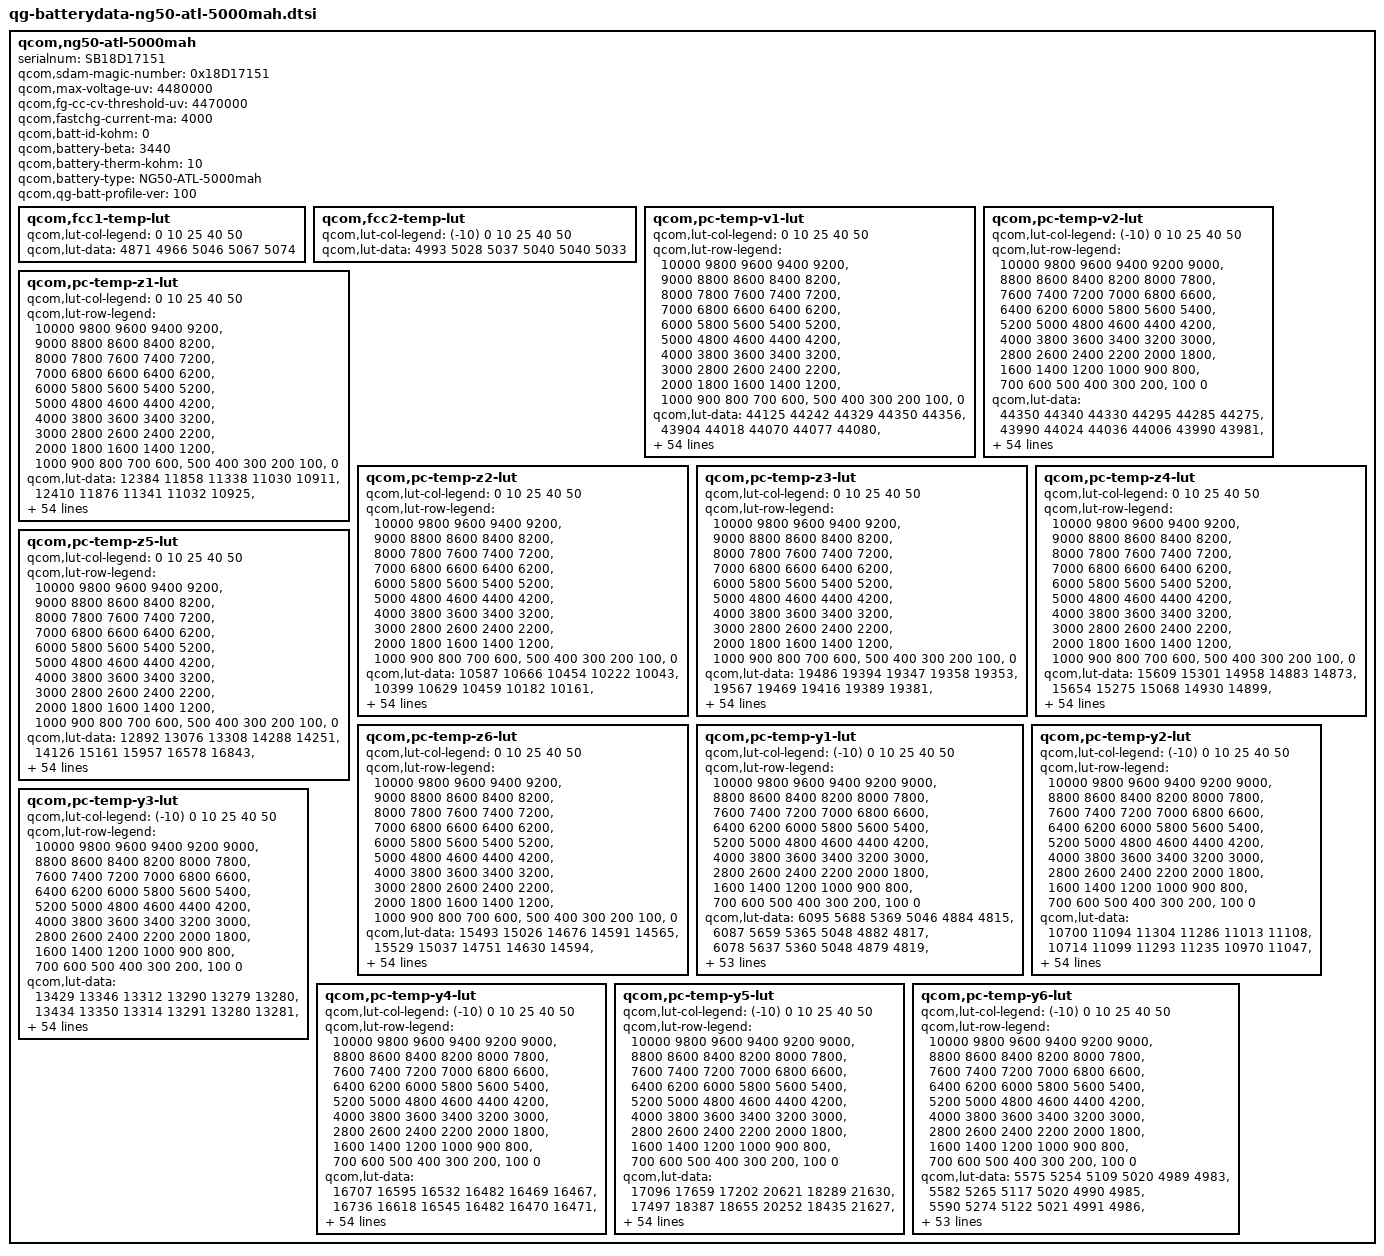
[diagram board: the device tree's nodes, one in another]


qcom,ng50-atl-5000mah {
    /* 5263304_Lenovo_Guogu_ATL_5000mAH_PM7250B_averaged_MasterSlave_Jun22th2021 */
    serialnum = "SB18D17151";
    qcom,sdam-magic-number = <0x18D17151>;
    qcom,max-voltage-uv = <4480000>;
    qcom,fg-cc-cv-threshold-uv = <4470000>;
    qcom,fastchg-current-ma = <4000>;
    qcom,batt-id-kohm = <0>;
    qcom,battery-beta = <3440>;
    qcom,battery-therm-kohm = <10>;
    qcom,battery-type = "NG50-ATL-5000mah";
    qcom,qg-batt-profile-ver = <100>;

	qcom,fcc1-temp-lut {
		qcom,lut-col-legend = <0 10 25 40 50>;
		qcom,lut-data = <4871 4966 5046 5067 5074>;
	};

	qcom,fcc2-temp-lut {
		qcom,lut-col-legend = <(-10) 0 10 25 40 50>;
		qcom,lut-data = <4993 5028 5037 5040 5040 5033>;
	};

	qcom,pc-temp-v1-lut {
		qcom,lut-col-legend = <0 10 25 40 50>;
		qcom,lut-row-legend = <10000 9800 9600 9400 9200>,
			<9000 8800 8600 8400 8200>,
			<8000 7800 7600 7400 7200>,
			<7000 6800 6600 6400 6200>,
			<6000 5800 5600 5400 5200>,
			<5000 4800 4600 4400 4200>,
			<4000 3800 3600 3400 3200>,
			<3000 2800 2600 2400 2200>,
			<2000 1800 1600 1400 1200>,
			<1000 900 800 700 600>,
			<500 400 300 200 100>,
			<0>;
		qcom,lut-data = <44125 44242 44329 44350 44356>,
			<43904 44018 44070 44077 44080>,
			<43680 43794 43852 43854 43854>,
			<43454 43573 43639 43642 43642>,
			<43224 43354 43415 43423 43422>,
			<42985 43125 43189 43202 43202>,
			<42743 42886 42955 42973 42975>,
			<42504 42643 42714 42734 42741>,
			<42265 42402 42473 42492 42504>,
			<42031 42161 42233 42251 42265>,
			<41803 41926 41994 42012 42024>,
			<41581 41694 41759 41777 41787>,
			<41365 41468 41526 41546 41554>,
			<41157 41249 41299 41319 41326>,
			<40952 41036 41079 41097 41105>,
			<40751 40830 40867 40881 40891>,
			<40554 40627 40664 40675 40683>,
			<40368 40434 40469 40475 40481>,
			<40190 40259 40283 40286 40289>,
			<40018 40097 40113 40117 40118>,
			<39855 39918 39940 39949 39950>,
			<39696 39700 39726 39736 39738>,
			<39509 39474 39479 39471 39471>,
			<39233 39260 39263 39246 39245>,
			<38979 39051 39078 39083 39092>,
			<38862 38900 38923 38947 38964>,
			<38795 38807 38810 38831 38837>,
			<38734 38731 38719 38732 38714>,
			<38671 38650 38630 38634 38607>,
			<38610 38571 38540 38531 38513>,
			<38550 38495 38457 38435 38430>,
			<38490 38422 38380 38354 38351>,
			<38433 38354 38309 38284 38278>,
			<38379 38295 38246 38217 38208>,
			<38329 38244 38193 38157 38140>,
			<38284 38197 38142 38098 38074>,
			<38246 38156 38092 38037 38006>,
			<38203 38113 38043 37975 37935>,
			<38137 38051 37977 37898 37849>,
			<38047 37962 37886 37793 37735>,
			<37943 37859 37782 37676 37611>,
			<37819 37738 37670 37566 37495>,
			<37674 37598 37541 37446 37370>,
			<37496 37425 37374 37285 37199>,
			<37333 37259 37220 37146 37064>,
			<37211 37147 37109 37050 36988>,
			<37176 37110 37073 37019 36961>,
			<37161 37088 37052 36992 36937>,
			<37127 37061 37029 36973 36913>,
			<37083 37024 36993 36924 36855>,
			<36940 36861 36801 36699 36606>,
			<36521 36434 36375 36268 36177>,
			<35947 35860 35804 35698 35606>,
			<35158 35064 35025 34922 34829>,
			<33838 33765 33823 33728 33632>,
			<30000 30000 30000 30000 30000>;
	};

	qcom,pc-temp-v2-lut {
		qcom,lut-col-legend = <(-10) 0 10 25 40 50>;
		qcom,lut-row-legend = <10000 9800 9600 9400 9200 9000>,
			<8800 8600 8400 8200 8000 7800>,
			<7600 7400 7200 7000 6800 6600>,
			<6400 6200 6000 5800 5600 5400>,
			<5200 5000 4800 4600 4400 4200>,
			<4000 3800 3600 3400 3200 3000>,
			<2800 2600 2400 2200 2000 1800>,
			<1600 1400 1200 1000 900 800>,
			<700 600 500 400 300 200>,
			<100 0>;
		qcom,lut-data = <44350 44340 44330 44295 44285 44275>,
			<43990 44024 44036 44006 43990 43981>,
			<43666 43736 43767 43738 43718 43711>,
			<43387 43482 43524 43493 43471 43466>,
			<43147 43261 43309 43272 43251 43248>,
			<42912 43037 43089 43049 43029 43029>,
			<42664 42797 42851 42811 42794 42796>,
			<42417 42551 42607 42570 42555 42557>,
			<42175 42307 42364 42328 42315 42318>,
			<41940 42064 42120 42085 42074 42075>,
			<41704 41825 41881 41846 41836 41836>,
			<41453 41588 41645 41611 41602 41600>,
			<41207 41359 41414 41380 41373 41369>,
			<41014 41142 41187 41153 41149 41145>,
			<40872 40935 40966 40931 40929 40927>,
			<40699 40733 40752 40717 40716 40715>,
			<40386 40542 40544 40510 40510 40508>,
			<40005 40345 40342 40311 40311 40309>,
			<39737 40111 40153 40126 40125 40124>,
			<39543 39836 39975 39951 39950 39950>,
			<39359 39577 39772 39759 39764 39766>,
			<39159 39346 39508 39527 39554 39559>,
			<38961 39134 39240 39290 39336 39345>,
			<38769 38945 39032 39080 39123 39135>,
			<38577 38773 38856 38884 38911 38925>,
			<38418 38620 38702 38723 38739 38752>,
			<38304 38486 38568 38594 38610 38620>,
			<38211 38364 38449 38483 38501 38507>,
			<38137 38243 38340 38382 38399 38402>,
			<38075 38127 38240 38289 38306 38305>,
			<38020 38036 38149 38203 38222 38217>,
			<37965 37969 38064 38120 38147 38141>,
			<37913 37916 37987 38043 38075 38067>,
			<37857 37872 37919 37974 38002 37992>,
			<37800 37838 37857 37912 37927 37915>,
			<37741 37802 37802 37843 37845 37828>,
			<37683 37764 37756 37766 37753 37719>,
			<37622 37722 37710 37684 37657 37606>,
			<37553 37668 37648 37601 37563 37511>,
			<37475 37602 37573 37515 37467 37422>,
			<37385 37512 37484 37424 37374 37332>,
			<37275 37366 37370 37330 37284 37241>,
			<37153 37204 37239 37216 37171 37126>,
			<37028 37043 37090 37071 37017 36965>,
			<36908 36882 36943 36955 36916 36865>,
			<36805 36780 36844 36887 36855 36805>,
			<36757 36745 36822 36870 36845 36792>,
			<36714 36711 36799 36859 36831 36777>,
			<36673 36666 36758 36832 36806 36752>,
			<36621 36587 36685 36767 36744 36678>,
			<36524 36399 36474 36519 36490 36410>,
			<36260 35988 35996 36044 36027 35935>,
			<35749 35357 35339 35409 35406 35309>,
			<35004 34477 34464 34542 34552 34447>,
			<33902 33111 33145 33244 33317 33248>,
			<31942 29637 29195 29227 29401 29421>;
	};

	qcom,pc-temp-z1-lut {
		qcom,lut-col-legend = <0 10 25 40 50>;
		qcom,lut-row-legend = <10000 9800 9600 9400 9200>,
			<9000 8800 8600 8400 8200>,
			<8000 7800 7600 7400 7200>,
			<7000 6800 6600 6400 6200>,
			<6000 5800 5600 5400 5200>,
			<5000 4800 4600 4400 4200>,
			<4000 3800 3600 3400 3200>,
			<3000 2800 2600 2400 2200>,
			<2000 1800 1600 1400 1200>,
			<1000 900 800 700 600>,
			<500 400 300 200 100>,
			<0>;
		qcom,lut-data = <12384 11858 11338 11030 10911>,
			<12410 11876 11341 11032 10925>,
			<12414 11885 11338 11035 10933>,
			<12416 11882 11334 11036 10939>,
			<12412 11874 11325 11033 10937>,
			<12392 11864 11314 11027 10933>,
			<12367 11837 11304 11022 10930>,
			<12355 11810 11294 11017 10929>,
			<12345 11798 11286 11014 10928>,
			<12334 11791 11279 11012 10927>,
			<12309 11784 11273 11011 10926>,
			<12280 11774 11269 11010 10925>,
			<12270 11767 11266 11009 10924>,
			<12269 11765 11264 11008 10924>,
			<12266 11765 11263 11007 10924>,
			<12249 11764 11262 11006 10925>,
			<12221 11753 11262 11006 10926>,
			<12208 11742 11265 11008 10928>,
			<12208 11743 11268 11011 10930>,
			<12210 11749 11269 11012 10933>,
			<12213 11752 11271 11014 10935>,
			<12222 11754 11274 11015 10937>,
			<12226 11754 11277 11016 10938>,
			<12228 11754 11280 11017 10939>,
			<12229 11754 11282 11020 10941>,
			<12226 11754 11286 11024 10944>,
			<12217 11758 11291 11027 10947>,
			<12214 11763 11298 11031 10950>,
			<12223 11766 11304 11035 10953>,
			<12236 11770 11307 11039 10957>,
			<12243 11773 11311 11042 10961>,
			<12250 11778 11316 11047 10965>,
			<12254 11781 11322 11051 10969>,
			<12251 11781 11328 11056 10973>,
			<12247 11779 11334 11061 10978>,
			<12247 11778 11340 11065 10982>,
			<12255 11784 11346 11070 10986>,
			<12263 11795 11352 11075 10990>,
			<12275 11807 11360 11080 10994>,
			<12297 11823 11368 11086 10999>,
			<12312 11835 11377 11091 11004>,
			<12319 11841 11387 11096 11007>,
			<12332 11844 11398 11101 11010>,
			<12379 11849 11406 11104 11012>,
			<12378 11859 11416 11110 11017>,
			<12362 11864 11428 11114 11019>,
			<12350 11867 11430 11115 11019>,
			<12378 11871 11424 11115 11020>,
			<12363 11888 11426 11118 11020>,
			<12360 11889 11435 11122 11025>,
			<12379 11890 11449 11131 11019>,
			<12377 11894 11461 11135 11037>,
			<12434 11931 11479 11151 11046>,
			<12429 11959 11510 11170 11065>,
			<12429 11959 11510 11170 11065>,
			<12429 11959 11510 11170 11065>;
	};

	qcom,pc-temp-z2-lut {
		qcom,lut-col-legend = <0 10 25 40 50>;
		qcom,lut-row-legend = <10000 9800 9600 9400 9200>,
			<9000 8800 8600 8400 8200>,
			<8000 7800 7600 7400 7200>,
			<7000 6800 6600 6400 6200>,
			<6000 5800 5600 5400 5200>,
			<5000 4800 4600 4400 4200>,
			<4000 3800 3600 3400 3200>,
			<3000 2800 2600 2400 2200>,
			<2000 1800 1600 1400 1200>,
			<1000 900 800 700 600>,
			<500 400 300 200 100>,
			<0>;
		qcom,lut-data = <10587 10666 10454 10222 10043>,
			<10399 10629 10459 10182 10161>,
			<10399 10597 10474 10279 10264>,
			<10426 10572 10485 10352 10321>,
			<10435 10550 10479 10343 10327>,
			<10404 10524 10462 10311 10318>,
			<10360 10483 10433 10282 10299>,
			<10340 10445 10371 10251 10239>,
			<10326 10424 10332 10231 10190>,
			<10321 10408 10323 10235 10192>,
			<10320 10403 10319 10246 10202>,
			<10320 10408 10321 10246 10206>,
			<10322 10417 10332 10231 10214>,
			<10336 10430 10346 10221 10221>,
			<10357 10456 10361 10239 10215>,
			<10386 10478 10377 10268 10206>,
			<10423 10494 10385 10275 10206>,
			<10451 10508 10390 10274 10212>,
			<10473 10519 10397 10273 10209>,
			<10489 10528 10409 10255 10190>,
			<10499 10539 10428 10234 10170>,
			<10506 10558 10476 10306 10230>,
			<10512 10574 10566 10567 10528>,
			<10519 10570 10597 10700 10697>,
			<10523 10550 10507 10508 10517>,
			<10522 10540 10414 10266 10278>,
			<10517 10553 10422 10249 10364>,
			<10514 10572 10465 10296 10798>,
			<10521 10581 10497 10353 11005>,
			<10533 10588 10523 10483 10798>,
			<10542 10593 10538 10602 10510>,
			<10553 10596 10536 10566 10365>,
			<10563 10599 10527 10425 10264>,
			<10574 10603 10517 10317 10196>,
			<10584 10606 10500 10241 10143>,
			<10593 10611 10488 10196 10112>,
			<10600 10622 10499 10208 10130>,
			<10608 10637 10529 10253 10189>,
			<10618 10650 10567 10308 10245>,
			<10629 10664 10628 10430 10298>,
			<10634 10672 10666 10535 10343>,
			<10636 10671 10658 10548 10378>,
			<10640 10671 10645 10534 10411>,
			<10677 10688 10639 10544 10499>,
			<10941 10817 10664 10502 10482>,
			<11011 10897 10691 10361 10313>,
			<10975 10886 10659 10408 10277>,
			<10792 10911 10648 10376 10313>,
			<10571 10920 10642 10393 10310>,
			<10443 10959 10623 10498 10401>,
			<10333 11037 10695 10396 10316>,
			<10294 11028 10622 10209 10111>,
			<10055 11056 10544 10149 10041>,
			<9916 10926 10487 10093 9990>,
			<9916 10926 10487 10093 9990>,
			<9916 10926 10487 10093 9990>;
	};

	qcom,pc-temp-z3-lut {
		qcom,lut-col-legend = <0 10 25 40 50>;
		qcom,lut-row-legend = <10000 9800 9600 9400 9200>,
			<9000 8800 8600 8400 8200>,
			<8000 7800 7600 7400 7200>,
			<7000 6800 6600 6400 6200>,
			<6000 5800 5600 5400 5200>,
			<5000 4800 4600 4400 4200>,
			<4000 3800 3600 3400 3200>,
			<3000 2800 2600 2400 2200>,
			<2000 1800 1600 1400 1200>,
			<1000 900 800 700 600>,
			<500 400 300 200 100>,
			<0>;
		qcom,lut-data = <19486 19394 19347 19358 19353>,
			<19567 19469 19416 19389 19381>,
			<19615 19519 19433 19403 19395>,
			<19650 19536 19445 19412 19403>,
			<19672 19547 19459 19420 19413>,
			<19687 19551 19470 19427 19421>,
			<19696 19553 19472 19432 19424>,
			<19697 19553 19472 19437 19424>,
			<19697 19553 19471 19439 19423>,
			<19697 19551 19465 19436 19421>,
			<19693 19548 19455 19430 19416>,
			<19685 19542 19449 19424 19413>,
			<19676 19535 19445 19419 19410>,
			<19664 19528 19441 19415 19407>,
			<19655 19522 19438 19411 19403>,
			<19649 19516 19434 19407 19398>,
			<19645 19513 19429 19403 19393>,
			<19638 19510 19423 19400 19389>,
			<19623 19504 19418 19395 19385>,
			<19611 19496 19414 19387 19378>,
			<19613 19494 19412 19378 19371>,
			<19620 19505 19416 19380 19371>,
			<19627 19519 19430 19391 19378>,
			<19636 19518 19435 19396 19381>,
			<19642 19509 19421 19380 19367>,
			<19640 19502 19405 19359 19349>,
			<19629 19496 19400 19358 19361>,
			<19620 19492 19396 19361 19414>,
			<19615 19494 19396 19367 19440>,
			<19612 19502 19408 19395 19434>,
			<19611 19507 19422 19424 19424>,
			<19611 19510 19430 19424 19415>,
			<19611 19512 19436 19415 19406>,
			<19610 19511 19437 19405 19396>,
			<19607 19506 19432 19394 19384>,
			<19605 19501 19424 19384 19372>,
			<19602 19497 19417 19374 19364>,
			<19598 19493 19411 19366 19357>,
			<19593 19489 19408 19364 19355>,
			<19587 19484 19407 19368 19355>,
			<19580 19479 19406 19371 19355>,
			<19572 19474 19401 19371 19359>,
			<19562 19468 19395 19370 19366>,
			<19550 19462 19394 19373 19373>,
			<19489 19441 19386 19369 19371>,
			<19467 19420 19375 19361 19361>,
			<19443 19419 19375 19352 19351>,
			<19308 19407 19369 19348 19338>,
			<19289 19405 19367 19335 19330>,
			<19281 19398 19351 19333 19328>,
			<19263 19387 19367 19346 19340>,
			<19263 19389 19381 19371 19359>,
			<19265 19338 19385 19371 19361>,
			<19271 19338 19387 19372 19361>,
			<19271 19338 19387 19372 19361>,
			<19271 19338 19387 19372 19361>;
	};

	qcom,pc-temp-z4-lut {
		qcom,lut-col-legend = <0 10 25 40 50>;
		qcom,lut-row-legend = <10000 9800 9600 9400 9200>,
			<9000 8800 8600 8400 8200>,
			<8000 7800 7600 7400 7200>,
			<7000 6800 6600 6400 6200>,
			<6000 5800 5600 5400 5200>,
			<5000 4800 4600 4400 4200>,
			<4000 3800 3600 3400 3200>,
			<3000 2800 2600 2400 2200>,
			<2000 1800 1600 1400 1200>,
			<1000 900 800 700 600>,
			<500 400 300 200 100>,
			<0>;
		qcom,lut-data = <15609 15301 14958 14883 14873>,
			<15654 15275 15068 14930 14899>,
			<15609 15233 15016 14905 14880>,
			<15451 15167 14959 14870 14852>,
			<15310 15072 14911 14843 14829>,
			<15207 14997 14867 14816 14806>,
			<15119 14943 14834 14792 14785>,
			<15050 14899 14808 14770 14766>,
			<14993 14863 14785 14752 14751>,
			<14947 14832 14765 14739 14741>,
			<14909 14807 14748 14728 14734>,
			<14877 14782 14738 14722 14728>,
			<14852 14764 14731 14717 14724>,
			<14831 14755 14725 14713 14721>,
			<14814 14749 14718 14708 14717>,
			<14796 14747 14713 14703 14713>,
			<14782 14746 14709 14699 14710>,
			<14779 14745 14707 14695 14708>,
			<14788 14742 14704 14692 14705>,
			<14796 14734 14699 14686 14697>,
			<14790 14732 14695 14682 14689>,
			<14773 14744 14705 14691 14698>,
			<14770 14767 14741 14739 14749>,
			<14834 14800 14778 14782 14792>,
			<14906 14851 14821 14814 14815>,
			<14911 14873 14850 14836 14829>,
			<14897 14862 14848 14834 14812>,
			<14882 14844 14835 14815 14741>,
			<14868 14826 14818 14790 14703>,
			<14853 14804 14793 14746 14699>,
			<14840 14788 14768 14708 14696>,
			<14826 14776 14750 14699 14692>,
			<14816 14767 14734 14696 14688>,
			<14810 14763 14726 14693 14684>,
			<14805 14761 14721 14692 14681>,
			<14800 14759 14719 14691 14679>,
			<14794 14755 14718 14690 14678>,
			<14789 14752 14718 14690 14677>,
			<14782 14749 14718 14691 14678>,
			<14776 14746 14722 14702 14695>,
			<14767 14743 14726 14711 14710>,
			<14753 14731 14721 14707 14703>,
			<14737 14716 14712 14700 14692>,
			<14719 14703 14707 14699 14695>,
			<14696 14678 14688 14688 14687>,
			<14688 14666 14671 14671 14664>,
			<14709 14662 14666 14671 14664>,
			<14850 14661 14657 14663 14661>,
			<14865 14652 14642 14652 14647>,
			<14867 14653 14647 14635 14629>,
			<14883 14671 14646 14657 14665>,
			<14895 14678 14655 14663 14677>,
			<14895 14739 14653 14670 14684>,
			<14896 14744 14655 14674 14690>,
			<14896 14744 14655 14674 14690>,
			<14896 14744 14655 14674 14690>;
	};

	qcom,pc-temp-z5-lut {
		qcom,lut-col-legend = <0 10 25 40 50>;
		qcom,lut-row-legend = <10000 9800 9600 9400 9200>,
			<9000 8800 8600 8400 8200>,
			<8000 7800 7600 7400 7200>,
			<7000 6800 6600 6400 6200>,
			<6000 5800 5600 5400 5200>,
			<5000 4800 4600 4400 4200>,
			<4000 3800 3600 3400 3200>,
			<3000 2800 2600 2400 2200>,
			<2000 1800 1600 1400 1200>,
			<1000 900 800 700 600>,
			<500 400 300 200 100>,
			<0>;
		qcom,lut-data = <12892 13076 13308 14288 14251>,
			<14126 15161 15957 16578 16843>,
			<15053 16676 16835 17969 18649>,
			<15811 17471 17596 18969 20003>,
			<16592 17998 18648 19975 21607>,
			<17429 18585 19644 20889 23192>,
			<18308 19267 20338 21973 24300>,
			<19280 20016 20893 23471 25033>,
			<20355 20866 21362 24767 25736>,
			<21437 21826 21725 25644 26628>,
			<22505 22889 22069 26390 27609>,
			<23555 24278 22542 26747 28557>,
			<24497 25534 23158 26957 29545>,
			<25256 26214 23841 27262 30283>,
			<26266 26779 24782 28148 30753>,
			<29135 27306 25573 29551 31248>,
			<33153 28356 25689 30889 31927>,
			<34006 29289 25631 32423 33552>,
			<31178 29038 25678 33159 34724>,
			<28620 28039 26451 32398 34981>,
			<29979 27849 27878 31312 35178>,
			<34481 35582 31590 32613 36065>,
			<39191 44412 39258 38682 38688>,
			<44993 43344 41879 41779 40033>,
			<49536 36354 33480 32494 31264>,
			<48131 30958 23893 20444 19607>,
			<41091 27840 21158 18083 21191>,
			<36282 25854 19635 17371 32671>,
			<34895 26066 19359 17396 38270>,
			<34077 27881 20819 23680 37366>,
			<34253 30149 23168 30855 36217>,
			<35933 33498 26288 31900 35701>,
			<37814 36947 30279 31826 34956>,
			<39313 38718 32635 31308 34002>,
			<40694 39947 34011 29920 31986>,
			<41453 40395 34803 28636 30208>,
			<41943 40225 34748 28269 29843>,
			<42220 39856 34227 28091 29660>,
			<42143 39273 34045 28421 29654>,
			<41756 38147 33966 31303 30108>,
			<41182 36910 33716 33752 30578>,
			<38966 35379 31052 31265 30387>,
			<37820 34500 27877 27471 30288>,
			<38884 34855 28787 29636 35963>,
			<35517 37142 29293 29775 38253>,
			<30986 33331 28471 26676 31261>,
			<27100 32216 28485 22053 23498>,
			<12739 26532 26965 21947 19528>,
			<12337 27607 29759 21121 20722>,
			<12150 26148 23182 24821 26867>,
			<11863 21110 28345 26779 27328>,
			<11792 20176 25296 24983 22196>,
			<11745 14384 25363 21625 19345>,
			<12368 14333 23809 19134 16879>,
			<12368 14333 23809 19134 16879>,
			<12368 14333 23809 19134 16879>;
	};

	qcom,pc-temp-z6-lut {
		qcom,lut-col-legend = <0 10 25 40 50>;
		qcom,lut-row-legend = <10000 9800 9600 9400 9200>,
			<9000 8800 8600 8400 8200>,
			<8000 7800 7600 7400 7200>,
			<7000 6800 6600 6400 6200>,
			<6000 5800 5600 5400 5200>,
			<5000 4800 4600 4400 4200>,
			<4000 3800 3600 3400 3200>,
			<3000 2800 2600 2400 2200>,
			<2000 1800 1600 1400 1200>,
			<1000 900 800 700 600>,
			<500 400 300 200 100>,
			<0>;
		qcom,lut-data = <15493 15026 14676 14591 14565>,
			<15529 15037 14751 14630 14594>,
			<15509 15040 14739 14624 14592>,
			<15435 15022 14724 14617 14589>,
			<15365 14973 14710 14610 14585>,
			<15309 14931 14694 14602 14579>,
			<15258 14901 14680 14594 14573>,
			<15214 14874 14667 14586 14565>,
			<15176 14851 14654 14579 14558>,
			<15142 14831 14640 14571 14552>,
			<15112 14812 14627 14563 14546>,
			<15085 14795 14619 14557 14541>,
			<15061 14781 14613 14552 14538>,
			<15039 14772 14608 14547 14534>,
			<15019 14766 14603 14542 14530>,
			<15003 14761 14598 14538 14525>,
			<14990 14758 14594 14534 14522>,
			<14981 14755 14589 14530 14518>,
			<14976 14750 14585 14526 14515>,
			<14972 14742 14582 14519 14507>,
			<14971 14739 14579 14513 14500>,
			<14970 14750 14586 14519 14505>,
			<14971 14768 14610 14548 14533>,
			<15004 14784 14627 14565 14550>,
			<15041 14802 14638 14569 14550>,
			<15042 14809 14644 14570 14549>,
			<15033 14803 14642 14569 14549>,
			<15023 14793 14635 14562 14548>,
			<15016 14788 14630 14558 14546>,
			<15009 14785 14627 14556 14542>,
			<15004 14782 14624 14554 14536>,
			<14999 14779 14621 14551 14530>,
			<14996 14777 14619 14545 14525>,
			<14995 14775 14616 14540 14518>,
			<14994 14773 14612 14534 14511>,
			<14994 14771 14608 14529 14505>,
			<14993 14770 14605 14524 14500>,
			<14993 14769 14603 14520 14496>,
			<14994 14769 14602 14519 14495>,
			<14995 14769 14606 14526 14502>,
			<14995 14769 14608 14532 14509>,
			<14992 14766 14605 14530 14509>,
			<14990 14761 14600 14528 14508>,
			<14990 14759 14599 14529 14513>,
			<14966 14746 14590 14523 14510>,
			<14958 14734 14579 14512 14495>,
			<14956 14732 14577 14508 14489>,
			<14947 14726 14570 14502 14482>,
			<14946 14723 14564 14491 14471>,
			<14949 14724 14559 14483 14462>,
			<14954 14732 14570 14500 14484>,
			<14971 14743 14584 14519 14504>,
			<14982 14752 14589 14525 14511>,
			<15004 14765 14597 14532 14518>,
			<15004 14765 14597 14532 14518>,
			<15004 14765 14597 14532 14518>;
	};

	qcom,pc-temp-y1-lut {
		qcom,lut-col-legend = <(-10) 0 10 25 40 50>;
		qcom,lut-row-legend = <10000 9800 9600 9400 9200 9000>,
			<8800 8600 8400 8200 8000 7800>,
			<7600 7400 7200 7000 6800 6600>,
			<6400 6200 6000 5800 5600 5400>,
			<5200 5000 4800 4600 4400 4200>,
			<4000 3800 3600 3400 3200 3000>,
			<2800 2600 2400 2200 2000 1800>,
			<1600 1400 1200 1000 900 800>,
			<700 600 500 400 300 200>,
			<100 0>;
		qcom,lut-data = <6095 5688 5369 5046 4884 4815>,
			<6087 5659 5365 5048 4882 4817>,
			<6078 5637 5360 5048 4879 4819>,
			<6069 5621 5354 5047 4877 4820>,
			<6062 5612 5349 5044 4875 4820>,
			<6059 5610 5346 5041 4873 4820>,
			<6060 5617 5343 5036 4871 4818>,
			<6062 5628 5341 5031 4870 4816>,
			<6069 5628 5335 5028 4869 4816>,
			<6094 5617 5325 5027 4869 4816>,
			<6109 5609 5320 5027 4868 4817>,
			<6104 5605 5322 5025 4868 4817>,
			<6094 5603 5325 5024 4867 4817>,
			<6092 5605 5324 5023 4867 4817>,
			<6090 5616 5321 5023 4868 4817>,
			<6089 5626 5319 5022 4868 4817>,
			<6093 5636 5317 5023 4868 4818>,
			<6095 5645 5316 5024 4868 4820>,
			<6097 5646 5315 5025 4868 4821>,
			<6096 5647 5315 5026 4869 4822>,
			<6092 5647 5314 5028 4870 4823>,
			<6085 5640 5318 5030 4872 4825>,
			<6079 5633 5323 5032 4876 4827>,
			<6079 5634 5329 5035 4878 4829>,
			<6086 5640 5334 5038 4881 4831>,
			<6092 5644 5336 5042 4883 4832>,
			<6085 5643 5335 5047 4885 4834>,
			<6073 5640 5333 5052 4887 4835>,
			<6073 5641 5336 5056 4890 4838>,
			<6089 5645 5344 5060 4893 4841>,
			<6101 5650 5349 5064 4896 4844>,
			<6091 5654 5349 5069 4898 4847>,
			<6074 5656 5349 5075 4901 4849>,
			<6071 5655 5351 5081 4906 4851>,
			<6076 5650 5354 5089 4913 4852>,
			<6080 5648 5356 5093 4917 4854>,
			<6078 5652 5358 5095 4918 4856>,
			<6076 5658 5359 5095 4919 4858>,
			<6077 5657 5365 5097 4919 4861>,
			<6080 5654 5374 5100 4918 4863>,
			<6082 5652 5382 5102 4918 4865>,
			<6093 5653 5393 5106 4921 4866>,
			<6103 5655 5397 5109 4924 4867>,
			<6107 5672 5392 5112 4925 4867>,
			<6099 5665 5417 5117 4928 4871>,
			<6133 5687 5404 5123 4931 4872>,
			<6152 5671 5409 5130 4932 4875>,
			<6153 5672 5404 5127 4931 4872>,
			<6134 5692 5415 5129 4931 4874>,
			<6157 5691 5410 5130 4932 4876>,
			<6193 5694 5424 5126 4933 4874>,
			<6223 5735 5423 5137 4937 4878>,
			<6317 5787 5446 5151 4944 4887>,
			<6405 5876 5475 5165 4954 4897>,
			<6405 5876 5475 5165 4954 4897>,
			<6405 5876 5475 5165 4954 4897>;
	};

	qcom,pc-temp-y2-lut {
		qcom,lut-col-legend = <(-10) 0 10 25 40 50>;
		qcom,lut-row-legend = <10000 9800 9600 9400 9200 9000>,
			<8800 8600 8400 8200 8000 7800>,
			<7600 7400 7200 7000 6800 6600>,
			<6400 6200 6000 5800 5600 5400>,
			<5200 5000 4800 4600 4400 4200>,
			<4000 3800 3600 3400 3200 3000>,
			<2800 2600 2400 2200 2000 1800>,
			<1600 1400 1200 1000 900 800>,
			<700 600 500 400 300 200>,
			<100 0>;
		qcom,lut-data = <10700 11094 11304 11286 11013 11108>,
			<10714 11099 11293 11235 10970 11047>,
			<10740 11097 11275 11184 10926 10977>,
			<10769 11087 11251 11136 10885 10908>,
			<10793 11072 11222 11092 10849 10848>,
			<10804 11054 11189 11053 10819 10807>,
			<10805 11025 11146 11016 10794 10780>,
			<10805 10995 11102 10985 10773 10758>,
			<10803 10980 11074 10971 10761 10735>,
			<10793 10971 11052 10963 10750 10702>,
			<10787 10967 11043 10960 10745 10682>,
			<10848 10975 11045 10965 10762 10684>,
			<10945 10995 11050 10974 10785 10691>,
			<10966 11029 11062 10983 10785 10695>,
			<10958 11096 11089 10993 10764 10698>,
			<10953 11138 11124 11008 10754 10699>,
			<10981 11147 11176 11038 10761 10690>,
			<11028 11154 11240 11081 10774 10682>,
			<11052 11173 11304 11146 10806 10700>,
			<11068 11210 11377 11242 10885 10764>,
			<11076 11234 11404 11282 10981 10849>,
			<11072 11236 11367 11270 11133 11001>,
			<11063 11238 11324 11255 11258 11137>,
			<11049 11258 11333 11248 11231 11128>,
			<11018 11303 11378 11233 11114 11047>,
			<10961 11329 11408 11232 11060 11001>,
			<10546 11334 11418 11265 11067 10993>,
			<9924 11336 11428 11308 11084 10995>,
			<9759 11342 11454 11337 11105 11033>,
			<9733 11363 11499 11364 11138 11130>,
			<9718 11372 11518 11397 11178 11183>,
			<9707 11369 11519 11454 11254 11183>,
			<9699 11360 11518 11500 11318 11174>,
			<9692 11335 11514 11509 11313 11194>,
			<9687 11275 11504 11510 11278 11258>,
			<9682 11218 11490 11500 11265 11278>,
			<9678 11174 11461 11456 11275 11224>,
			<9675 11125 11426 11416 11281 11153>,
			<9673 11066 11393 11411 11252 11105>,
			<9671 10988 11358 11412 11198 11062>,
			<9670 10821 11315 11407 11174 11054>,
			<9668 10136 11255 11378 11187 11126>,
			<9667 9760 11178 11355 11187 11151>,
			<9666 9713 11075 11344 11150 11035>,
			<9664 9694 10958 11255 11009 10867>,
			<9662 9684 10668 11149 10921 10773>,
			<9662 9678 10709 11152 10891 10757>,
			<9660 9673 10753 11193 10933 10742>,
			<9659 9669 10694 11189 10961 10801>,
			<9657 9666 10615 11244 10957 10787>,
			<9653 9662 10500 11187 10867 10755>,
			<9651 9657 9920 11108 10801 10690>,
			<9650 9652 9701 11002 10724 10603>,
			<9649 9652 9664 10902 10610 10484>,
			<9649 9652 9664 10902 10610 10484>,
			<9649 9652 9664 10902 10610 10484>;
	};

	qcom,pc-temp-y3-lut {
		qcom,lut-col-legend = <(-10) 0 10 25 40 50>;
		qcom,lut-row-legend = <10000 9800 9600 9400 9200 9000>,
			<8800 8600 8400 8200 8000 7800>,
			<7600 7400 7200 7000 6800 6600>,
			<6400 6200 6000 5800 5600 5400>,
			<5200 5000 4800 4600 4400 4200>,
			<4000 3800 3600 3400 3200 3000>,
			<2800 2600 2400 2200 2000 1800>,
			<1600 1400 1200 1000 900 800>,
			<700 600 500 400 300 200>,
			<100 0>;
		qcom,lut-data = <13429 13346 13312 13290 13279 13280>,
			<13434 13350 13314 13291 13280 13281>,
			<13439 13356 13317 13292 13282 13282>,
			<13444 13360 13320 13293 13283 13283>,
			<13448 13364 13323 13294 13284 13284>,
			<13451 13367 13325 13295 13285 13285>,
			<13453 13369 13325 13296 13286 13285>,
			<13455 13370 13325 13296 13286 13286>,
			<13455 13372 13326 13297 13287 13287>,
			<13452 13374 13327 13298 13288 13287>,
			<13449 13376 13328 13298 13289 13287>,
			<13442 13374 13329 13300 13290 13287>,
			<13433 13372 13330 13301 13291 13288>,
			<13427 13369 13330 13301 13292 13289>,
			<13423 13367 13330 13300 13293 13291>,
			<13419 13364 13329 13300 13294 13292>,
			<13413 13363 13326 13301 13295 13292>,
			<13407 13361 13323 13301 13295 13292>,
			<13402 13358 13323 13301 13296 13293>,
			<13399 13354 13326 13301 13297 13296>,
			<13394 13349 13327 13300 13298 13297>,
			<13389 13345 13322 13299 13295 13294>,
			<13383 13342 13316 13297 13292 13290>,
			<13375 13338 13313 13295 13288 13286>,
			<13363 13335 13311 13292 13284 13283>,
			<13354 13332 13309 13290 13282 13281>,
			<13350 13330 13307 13289 13281 13281>,
			<13348 13328 13306 13289 13281 13281>,
			<13352 13324 13305 13289 13281 13281>,
			<13361 13319 13304 13290 13281 13280>,
			<13372 13316 13304 13290 13281 13279>,
			<13384 13315 13304 13290 13281 13279>,
			<13397 13314 13304 13289 13282 13279>,
			<13412 13316 13304 13289 13282 13280>,
			<13430 13322 13304 13289 13281 13281>,
			<13452 13328 13304 13289 13282 13282>,
			<13481 13331 13305 13289 13282 13281>,
			<13517 13335 13305 13288 13282 13280>,
			<13556 13338 13306 13288 13283 13281>,
			<13600 13342 13308 13288 13283 13282>,
			<13648 13347 13308 13288 13284 13284>,
			<13701 13353 13309 13289 13285 13284>,
			<13763 13363 13311 13289 13285 13284>,
			<13837 13384 13314 13288 13281 13281>,
			<13932 13414 13317 13290 13283 13283>,
			<14030 13437 13313 13291 13288 13286>,
			<14111 13476 13319 13295 13291 13289>,
			<14227 13530 13327 13301 13294 13290>,
			<14382 13598 13333 13303 13294 13292>,
			<14687 13703 13345 13305 13294 13291>,
			<15443 13879 13355 13301 13290 13288>,
			<17109 14280 13374 13301 13290 13290>,
			<21457 15694 13450 13306 13293 13293>,
			<34974 20643 13756 13315 13302 13302>,
			<34974 20643 13756 13315 13302 13302>,
			<34974 20643 13756 13315 13302 13302>;
	};

	qcom,pc-temp-y4-lut {
		qcom,lut-col-legend = <(-10) 0 10 25 40 50>;
		qcom,lut-row-legend = <10000 9800 9600 9400 9200 9000>,
			<8800 8600 8400 8200 8000 7800>,
			<7600 7400 7200 7000 6800 6600>,
			<6400 6200 6000 5800 5600 5400>,
			<5200 5000 4800 4600 4400 4200>,
			<4000 3800 3600 3400 3200 3000>,
			<2800 2600 2400 2200 2000 1800>,
			<1600 1400 1200 1000 900 800>,
			<700 600 500 400 300 200>,
			<100 0>;
		qcom,lut-data = <16707 16595 16532 16482 16469 16467>,
			<16736 16618 16545 16482 16470 16471>,
			<16790 16650 16557 16482 16470 16474>,
			<16852 16683 16567 16483 16470 16477>,
			<16903 16709 16574 16484 16470 16478>,
			<16927 16718 16576 16484 16470 16479>,
			<16929 16715 16573 16485 16470 16478>,
			<16931 16710 16569 16485 16470 16477>,
			<16935 16707 16568 16486 16470 16476>,
			<16949 16705 16568 16489 16471 16475>,
			<16965 16704 16568 16492 16473 16475>,
			<16978 16712 16572 16495 16474 16475>,
			<16994 16730 16578 16500 16477 16477>,
			<17028 16755 16587 16506 16480 16478>,
			<17108 16796 16602 16516 16483 16480>,
			<17156 16831 16622 16527 16488 16483>,
			<17048 16858 16657 16538 16494 16486>,
			<16866 16876 16693 16552 16501 16492>,
			<16810 16860 16707 16575 16514 16499>,
			<16798 16782 16715 16609 16534 16510>,
			<16785 16712 16716 16622 16542 16519>,
			<16752 16670 16660 16597 16541 16526>,
			<16708 16636 16584 16557 16541 16531>,
			<16668 16609 16549 16524 16527 16521>,
			<16624 16587 16525 16489 16486 16486>,
			<16602 16571 16515 16478 16468 16469>,
			<16619 16560 16510 16478 16469 16467>,
			<16648 16551 16508 16480 16471 16466>,
			<16659 16537 16508 16484 16474 16468>,
			<16664 16520 16509 16490 16482 16474>,
			<16669 16514 16509 16497 16490 16482>,
			<16674 16518 16508 16502 16501 16493>,
			<16679 16526 16507 16508 16510 16503>,
			<16686 16534 16505 16514 16514 16510>,
			<16697 16546 16503 16521 16517 16515>,
			<16706 16560 16503 16522 16517 16516>,
			<16713 16580 16513 16511 16508 16503>,
			<16718 16601 16525 16498 16497 16490>,
			<16722 16619 16532 16491 16491 16491>,
			<16727 16636 16538 16485 16487 16496>,
			<16730 16641 16543 16485 16488 16503>,
			<16722 16639 16548 16493 16498 16515>,
			<16708 16637 16553 16494 16497 16514>,
			<16694 16631 16558 16482 16464 16468>,
			<16692 16619 16554 16476 16453 16453>,
			<16685 16614 16550 16479 16466 16479>,
			<16692 16624 16559 16492 16498 16518>,
			<16708 16638 16572 16520 16536 16560>,
			<16727 16663 16599 16555 16575 16598>,
			<16774 16700 16641 16588 16595 16604>,
			<16946 16726 16658 16536 16522 16531>,
			<17283 16760 16664 16509 16487 16491>,
			<18462 17194 16706 16522 16487 16489>,
			<26525 21694 16813 16556 16489 16489>,
			<26525 21694 16813 16556 16489 16489>,
			<26525 21694 16813 16556 16489 16489>;
	};

	qcom,pc-temp-y5-lut {
		qcom,lut-col-legend = <(-10) 0 10 25 40 50>;
		qcom,lut-row-legend = <10000 9800 9600 9400 9200 9000>,
			<8800 8600 8400 8200 8000 7800>,
			<7600 7400 7200 7000 6800 6600>,
			<6400 6200 6000 5800 5600 5400>,
			<5200 5000 4800 4600 4400 4200>,
			<4000 3800 3600 3400 3200 3000>,
			<2800 2600 2400 2200 2000 1800>,
			<1600 1400 1200 1000 900 800>,
			<700 600 500 400 300 200>,
			<100 0>;
		qcom,lut-data = <17096 17659 17202 20621 18289 21630>,
			<17497 18387 18655 20252 18435 21627>,
			<17997 19030 19533 19812 18504 21623>,
			<18505 19544 19980 19342 18519 21617>,
			<18932 19882 20143 18884 18501 21613>,
			<19188 20000 20163 18478 18472 21612>,
			<19321 19878 19749 18103 18358 21636>,
			<19406 19637 19010 17719 18145 21641>,
			<19362 19415 18478 17307 17857 21374>,
			<19092 19175 18042 16834 17404 20357>,
			<18738 18850 17645 16463 17109 19408>,
			<17873 18232 17286 16258 17193 18681>,
			<16782 17490 16922 16067 17382 18080>,
			<17080 16948 16428 15646 17355 17934>,
			<19897 16467 15767 14889 17116 18096>,
			<21784 16298 15458 14429 16790 18091>,
			<21429 18419 15490 14262 16225 17405>,
			<20841 21349 15623 14163 15640 16608>,
			<20929 22120 16791 14246 15377 16425>,
			<22188 22381 20434 14696 15203 16373>,
			<23188 22633 22614 15489 15220 16418>,
			<23419 23183 23185 18774 17643 17933>,
			<23557 23700 23513 22102 20395 19928>,
			<23205 23698 23646 22326 20472 20658>,
			<20715 23484 23674 22046 19845 21109>,
			<18676 23383 23568 21652 19182 21228>,
			<16439 23541 22976 20773 18454 20387>,
			<13420 23722 22365 20007 17744 19053>,
			<12896 23024 22284 20194 17195 17813>,
			<13033 20460 22394 20878 16717 16491>,
			<13209 18575 22631 21137 16580 15872>,
			<13444 17465 23473 20911 16737 15701>,
			<13689 16754 24308 20696 17005 15693>,
			<13769 17209 24427 20954 17384 16418>,
			<13791 18820 24241 21747 18026 18285>,
			<13825 19939 23895 22487 18896 19383>,
			<14112 20567 23102 23328 20633 19732>,
			<14584 21096 22171 23895 21963 20069>,
			<14755 21568 21426 23376 21951 20893>,
			<14792 22051 20726 22044 21812 22158>,
			<14764 21968 20131 21248 21804 22626>,
			<14480 18060 19289 20785 22073 22553>,
			<14057 15501 18920 20361 22033 22521>,
			<13783 14996 19182 19686 21230 22701>,
			<13340 14701 19512 20210 21096 22135>,
			<13217 14187 17764 18955 19215 17780>,
			<13101 14199 18198 18629 18160 15992>,
			<13059 14394 18557 19588 16999 14977>,
			<13258 14289 17779 18769 16061 14818>,
			<13271 14159 17886 18630 15747 14434>,
			<12336 14444 18035 18980 15976 15081>,
			<10949 14198 15643 20213 17139 16296>,
			<9758 11775 14550 20630 17011 15821>,
			<9057 9474 13926 22347 19847 19073>,
			<9057 9474 13926 22347 19847 19073>,
			<9057 9474 13926 22347 19847 19073>;
	};

	qcom,pc-temp-y6-lut {
		qcom,lut-col-legend = <(-10) 0 10 25 40 50>;
		qcom,lut-row-legend = <10000 9800 9600 9400 9200 9000>,
			<8800 8600 8400 8200 8000 7800>,
			<7600 7400 7200 7000 6800 6600>,
			<6400 6200 6000 5800 5600 5400>,
			<5200 5000 4800 4600 4400 4200>,
			<4000 3800 3600 3400 3200 3000>,
			<2800 2600 2400 2200 2000 1800>,
			<1600 1400 1200 1000 900 800>,
			<700 600 500 400 300 200>,
			<100 0>;
		qcom,lut-data = <5575 5254 5109 5020 4989 4983>,
			<5582 5265 5117 5020 4990 4985>,
			<5590 5274 5122 5021 4991 4986>,
			<5596 5280 5125 5021 4992 4988>,
			<5601 5284 5126 5022 4993 4989>,
			<5602 5285 5126 5022 4993 4990>,
			<5601 5283 5124 5022 4994 4991>,
			<5599 5279 5120 5023 4994 4991>,
			<5597 5276 5119 5023 4995 4991>,
			<5595 5273 5117 5024 4996 4991>,
			<5593 5272 5117 5025 4997 4991>,
			<5591 5273 5118 5027 4998 4992>,
			<5589 5274 5119 5029 5000 4992>,
			<5592 5276 5121 5031 5001 4994>,
			<5614 5285 5124 5033 5003 4995>,
			<5628 5293 5128 5036 5005 4997>,
			<5597 5299 5135 5039 5007 4998>,
			<5546 5305 5143 5044 5009 5000>,
			<5531 5299 5148 5050 5014 5003>,
			<5528 5274 5152 5059 5020 5008>,
			<5525 5252 5153 5063 5023 5011>,
			<5517 5238 5133 5055 5021 5010>,
			<5506 5227 5107 5042 5018 5009>,
			<5497 5219 5096 5031 5010 5004>,
			<5487 5214 5088 5020 4996 4991>,
			<5482 5210 5085 5016 4990 4985>,
			<5486 5209 5084 5016 4990 4985>,
			<5496 5208 5083 5017 4990 4985>,
			<5509 5207 5084 5018 4992 4985>,
			<5529 5204 5085 5021 4994 4987>,
			<5551 5203 5087 5024 4997 4988>,
			<5572 5208 5088 5026 5000 4991>,
			<5595 5217 5089 5028 5003 4994>,
			<5621 5228 5090 5030 5005 4997>,
			<5651 5244 5091 5033 5006 5000>,
			<5684 5263 5094 5033 5007 5001>,
			<5719 5283 5099 5030 5004 4997>,
			<5757 5306 5106 5027 5002 4993>,
			<5797 5331 5112 5026 5001 4993>,
			<5840 5359 5118 5025 5000 4996>,
			<5886 5384 5126 5025 5000 4999>,
			<5932 5403 5134 5029 5004 5003>,
			<5984 5428 5145 5030 5004 5003>,
			<6049 5465 5160 5026 4992 4987>,
			<6134 5513 5174 5027 4991 4986>,
			<6227 5557 5174 5030 4999 4996>,
			<6300 5607 5194 5037 5011 5009>,
			<6408 5667 5217 5050 5024 5022>,
			<6555 5747 5246 5061 5035 5035>,
			<6840 5860 5289 5072 5042 5036>,
			<7537 6029 5332 5054 5017 5012>,
			<8953 6403 5387 5048 5008 5004>,
			<12507 7686 5522 5058 5011 5006>,
			<24051 12622 5887 5078 5019 5014>,
			<24051 12622 5887 5078 5019 5014>,
			<24051 12622 5887 5078 5019 5014>;
	};

};
